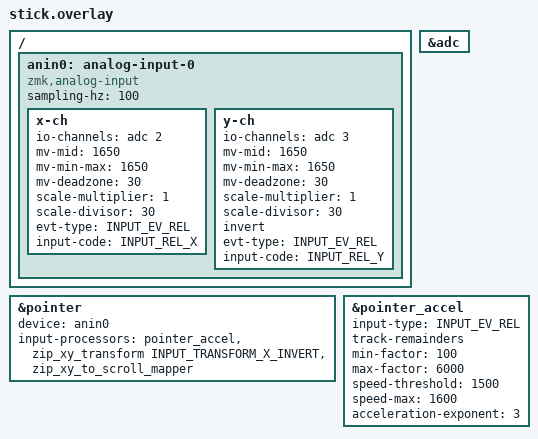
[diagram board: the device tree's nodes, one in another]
#include <input/processors.dtsi>
#include <zephyr/dt-bindings/input/input-event-codes.h>
#include <behaviors/input_gestures_accel.dtsi>

/ {
    anin0: analog-input-0 {
        compatible = "zmk,analog-input";
        sampling-hz = <100>;
        x-ch {
            io-channels = <&adc 2>;
            mv-mid = <1650>;
            mv-min-max = <1650>;
            mv-deadzone = <30>;
            scale-multiplier = <1>;
            scale-divisor = <30>;
            // invert;
            evt-type = <INPUT_EV_REL>;
            input-code = <INPUT_REL_X>;
            // report-on-change-only;
        };
        y-ch {
            io-channels = <&adc 3>;
            mv-mid = <1650>;
            mv-min-max = <1650>;
            mv-deadzone = <30>;
            scale-multiplier = <1>;
            scale-divisor = <30>;
            invert;
            evt-type = <INPUT_EV_REL>;
            input-code = <INPUT_REL_Y>;
            // report-on-change-only;
        };
    };
};

&adc {
    status = "okay";
};

&pointer {
    status = "okay";
    device = <&anin0>;
    input-processors
        = <&pointer_accel>
        , <&zip_xy_transform INPUT_TRANSFORM_X_INVERT>
        , <&zip_xy_to_scroll_mapper>
        ;
};

&pointer_accel {
    input-type = <INPUT_EV_REL>; // For relative input devices
    track-remainders; // Accumulate fractional movements
    min-factor = <100>;
    max-factor = <6000>;
    speed-threshold = <1500>;
    speed-max = <1600>;
    acceleration-exponent = <3>; // Quadratic acceleration curve
};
